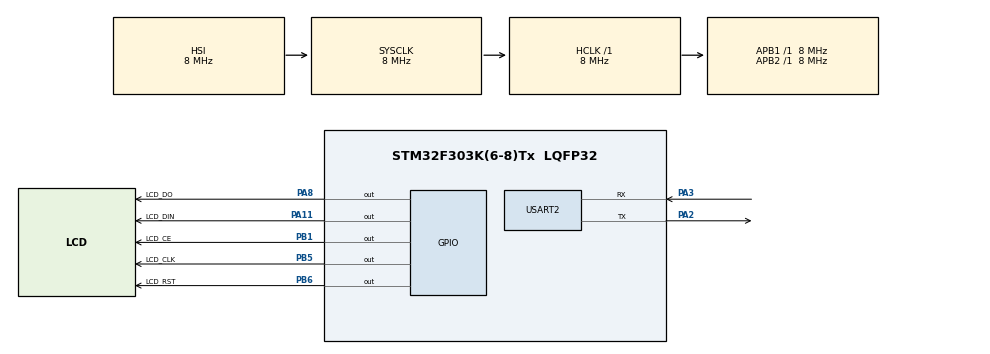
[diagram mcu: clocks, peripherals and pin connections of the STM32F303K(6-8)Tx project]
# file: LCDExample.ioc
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Dma.Request0=USART2_TX
Dma.USART2_TX.0.Direction=DMA_MEMORY_TO_PERIPH
Dma.USART2_TX.0.Instance=DMA1_Channel7
Dma.USART2_TX.0.MemDataAlignment=DMA_MDATAALIGN_BYTE
Dma.USART2_TX.0.MemInc=DMA_MINC_ENABLE
Dma.USART2_TX.0.Mode=DMA_NORMAL
Dma.USART2_TX.0.PeriphDataAlignment=DMA_PDATAALIGN_BYTE
Dma.USART2_TX.0.PeriphInc=DMA_PINC_DISABLE
Dma.USART2_TX.0.Priority=DMA_PRIORITY_LOW
Mcu.Family=STM32F3
Mcu.Name=STM32F303K(6-8)Tx
Mcu.Package=LQFP32
NVIC.DMA1_Channel7_IRQn=true\:0\:0\:false\:false\:true\:false\:true
NVIC.PriorityGroup=NVIC_PRIORITYGROUP_4
PA11.GPIO_Label=LCD_DIN
PA11.Signal=GPIO_Output
PA2.Mode=Asynchronous
PA2.Signal=USART2_TX
PA3.Mode=Asynchronous
PA3.Signal=USART2_RX
PA8.GPIO_Label=LCD_DO
PA8.Signal=GPIO_Output
PB1.GPIO_Label=LCD_CE
PB1.Signal=GPIO_Output
PB5.GPIO_Label=LCD_CLK
PB5.Signal=GPIO_Output
PB6.GPIO_Label=LCD_RST
PB6.Signal=GPIO_Output
PF0\ /\ OSC_IN.Mode=HSE-External-Oscillator
PF0\ /\ OSC_IN.Signal=RCC_OSC_IN
PF1\ /\ OSC_OUT.Mode=HSE-External-Oscillator
PF1\ /\ OSC_OUT.Signal=RCC_OSC_OUT
ProjectManager.HeapSize=0x200
ProjectManager.StackSize=0x400
ProjectManager.TargetToolchain=STM32CubeIDE
RCC.AHBFreq_Value=8000000
RCC.APB1Freq_Value=8000000
RCC.APB2Freq_Value=8000000
RCC.CortexFreq_Value=8000000
RCC.HSE_VALUE=8000000
RCC.HSI_VALUE=8000000
RCC.SYSCLKFreq_VALUE=8000000
USART2.VirtualMode-Asynchronous=VM_ASYNC
board=custom

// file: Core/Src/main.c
/* USER CODE BEGIN Header */
/**
  ******************************************************************************
  * @file           : main.c
  * @brief          : Main program body
  ******************************************************************************
  * @attention
  *
  * <h2><center>&copy; Copyright (c) 2021 STMicroelectronics.
  * All rights reserved.</center></h2>
  *
  * This software component is licensed by ST under BSD 3-Clause license,
  * the "License"; You may not use this file except in compliance with the
  * License. You may obtain a copy of the License at:
  *                        opensource.org/licenses/BSD-3-Clause
  *
  ******************************************************************************
  */
/* USER CODE END Header */
#include "main.h"

UART_HandleTypeDef huart2;
DMA_HandleTypeDef hdma_usart2_tx;

void SystemClock_Config(void);
static void MX_GPIO_Init(void);
static void MX_DMA_Init(void);
static void MX_USART2_UART_Init(void);

int main(void)
{

  /* MCU Configuration--------------------------------------------------------*/

  /* Reset of all peripherals, Initializes the Flash interface and the Systick. */
  HAL_Init();

  /* Configure the system clock */
  SystemClock_Config();

  /* Initialize all configured peripherals */
  MX_GPIO_Init();
  MX_DMA_Init();
  MX_USART2_UART_Init();

  /* USER CODE BEGIN 2 */
  uint8_t X=0;
  LCD_setRST(LCD_RST_GPIO_Port, LCD_RST_Pin);
  LCD_setCE(LCD_CE_GPIO_Port, LCD_CE_Pin);
  LCD_setDC(LCD_DO_GPIO_Port, LCD_DO_Pin);
  LCD_setDIN(LCD_DIN_GPIO_Port, LCD_DIN_Pin);
  LCD_setCLK(LCD_CLK_GPIO_Port, LCD_CLK_Pin);
  LCD_init();
  /* USER CODE END 2 */

  /* Infinite loop */
  while (1)
  {

	    /* USER CODE END WHILE */
		 uint8_t MSG[25] = {'\0'};
		 sprintf(MSG, "Tracing X = %d\n", X);
		 LCD_print(MSG, 0, 0);
		 HAL_UART_Transmit(&huart2, MSG, sizeof(MSG), 100);
		 HAL_Delay(500);
		 X++;

  }
}

void SystemClock_Config(void)
{
  RCC_OscInitTypeDef RCC_OscInitStruct = {0};
  RCC_ClkInitTypeDef RCC_ClkInitStruct = {0};

  /** Initializes the RCC Oscillators according to the specified parameters
  * in the RCC_OscInitTypeDef structure.
  */
  RCC_OscInitStruct.OscillatorType = RCC_OSCILLATORTYPE_HSI;
  RCC_OscInitStruct.HSIState = RCC_HSI_ON;
  RCC_OscInitStruct.HSICalibrationValue = RCC_HSICALIBRATION_DEFAULT;
  RCC_OscInitStruct.PLL.PLLState = RCC_PLL_NONE;
  if (HAL_RCC_OscConfig(&RCC_OscInitStruct) != HAL_OK)
  {
    Error_Handler();
  }
  /** Initializes the CPU, AHB and APB buses clocks
  */
  RCC_ClkInitStruct.ClockType = RCC_CLOCKTYPE_HCLK|RCC_CLOCKTYPE_SYSCLK
                              |RCC_CLOCKTYPE_PCLK1|RCC_CLOCKTYPE_PCLK2;
  RCC_ClkInitStruct.SYSCLKSource = RCC_SYSCLKSOURCE_HSI;
  RCC_ClkInitStruct.AHBCLKDivider = RCC_SYSCLK_DIV1;
  RCC_ClkInitStruct.APB1CLKDivider = RCC_HCLK_DIV1;
  RCC_ClkInitStruct.APB2CLKDivider = RCC_HCLK_DIV1;

  if (HAL_RCC_ClockConfig(&RCC_ClkInitStruct, FLASH_LATENCY_0) != HAL_OK)
  {
    Error_Handler();
  }
}

static void MX_USART2_UART_Init(void)
{

  huart2.Instance = USART2;
  huart2.Init.BaudRate = 38400;
  huart2.Init.WordLength = UART_WORDLENGTH_8B;
  huart2.Init.StopBits = UART_STOPBITS_1;
  huart2.Init.Parity = UART_PARITY_NONE;
  huart2.Init.Mode = UART_MODE_TX_RX;
  huart2.Init.HwFlowCtl = UART_HWCONTROL_NONE;
  huart2.Init.OverSampling = UART_OVERSAMPLING_16;
  huart2.Init.OneBitSampling = UART_ONE_BIT_SAMPLE_DISABLE;
  huart2.AdvancedInit.AdvFeatureInit = UART_ADVFEATURE_NO_INIT;
  if (HAL_UART_Init(&huart2) != HAL_OK)
  {
    Error_Handler();
  }

}

static void MX_DMA_Init(void)
{

  /* DMA controller clock enable */
  __HAL_RCC_DMA1_CLK_ENABLE();

  /* DMA interrupt init */
  /* DMA1_Channel7_IRQn interrupt configuration */
  HAL_NVIC_SetPriority(DMA1_Channel7_IRQn, 0, 0);
  HAL_NVIC_EnableIRQ(DMA1_Channel7_IRQn);

}

static void MX_GPIO_Init(void)
{
  GPIO_InitTypeDef GPIO_InitStruct = {0};

  /* GPIO Ports Clock Enable */
  __HAL_RCC_GPIOF_CLK_ENABLE();
  __HAL_RCC_GPIOA_CLK_ENABLE();
  __HAL_RCC_GPIOB_CLK_ENABLE();

  /*Configure GPIO pin Output Level */
  HAL_GPIO_WritePin(GPIOB, LCD_CE_Pin|LCD_CLK_Pin|LCD_RST_Pin, GPIO_PIN_RESET);

  /*Configure GPIO pin Output Level */
  HAL_GPIO_WritePin(GPIOA, LCD_DO_Pin|LCD_DIN_Pin, GPIO_PIN_RESET);

  /*Configure GPIO pins : LCD_CE_Pin LCD_CLK_Pin LCD_RST_Pin */
  GPIO_InitStruct.Pin = LCD_CE_Pin|LCD_CLK_Pin|LCD_RST_Pin;
  GPIO_InitStruct.Mode = GPIO_MODE_OUTPUT_PP;
  GPIO_InitStruct.Pull = GPIO_NOPULL;
  GPIO_InitStruct.Speed = GPIO_SPEED_FREQ_LOW;
  HAL_GPIO_Init(GPIOB, &GPIO_InitStruct);

  /*Configure GPIO pins : LCD_DO_Pin LCD_DIN_Pin */
  GPIO_InitStruct.Pin = LCD_DO_Pin|LCD_DIN_Pin;
  GPIO_InitStruct.Mode = GPIO_MODE_OUTPUT_PP;
  GPIO_InitStruct.Pull = GPIO_NOPULL;
  GPIO_InitStruct.Speed = GPIO_SPEED_FREQ_LOW;
  HAL_GPIO_Init(GPIOA, &GPIO_InitStruct);

}

void Error_Handler(void)
{
  __disable_irq();
  while (1)
  {
  }
}

/************************ (C) COPYRIGHT STMicroelectronics *****END OF FILE****/
